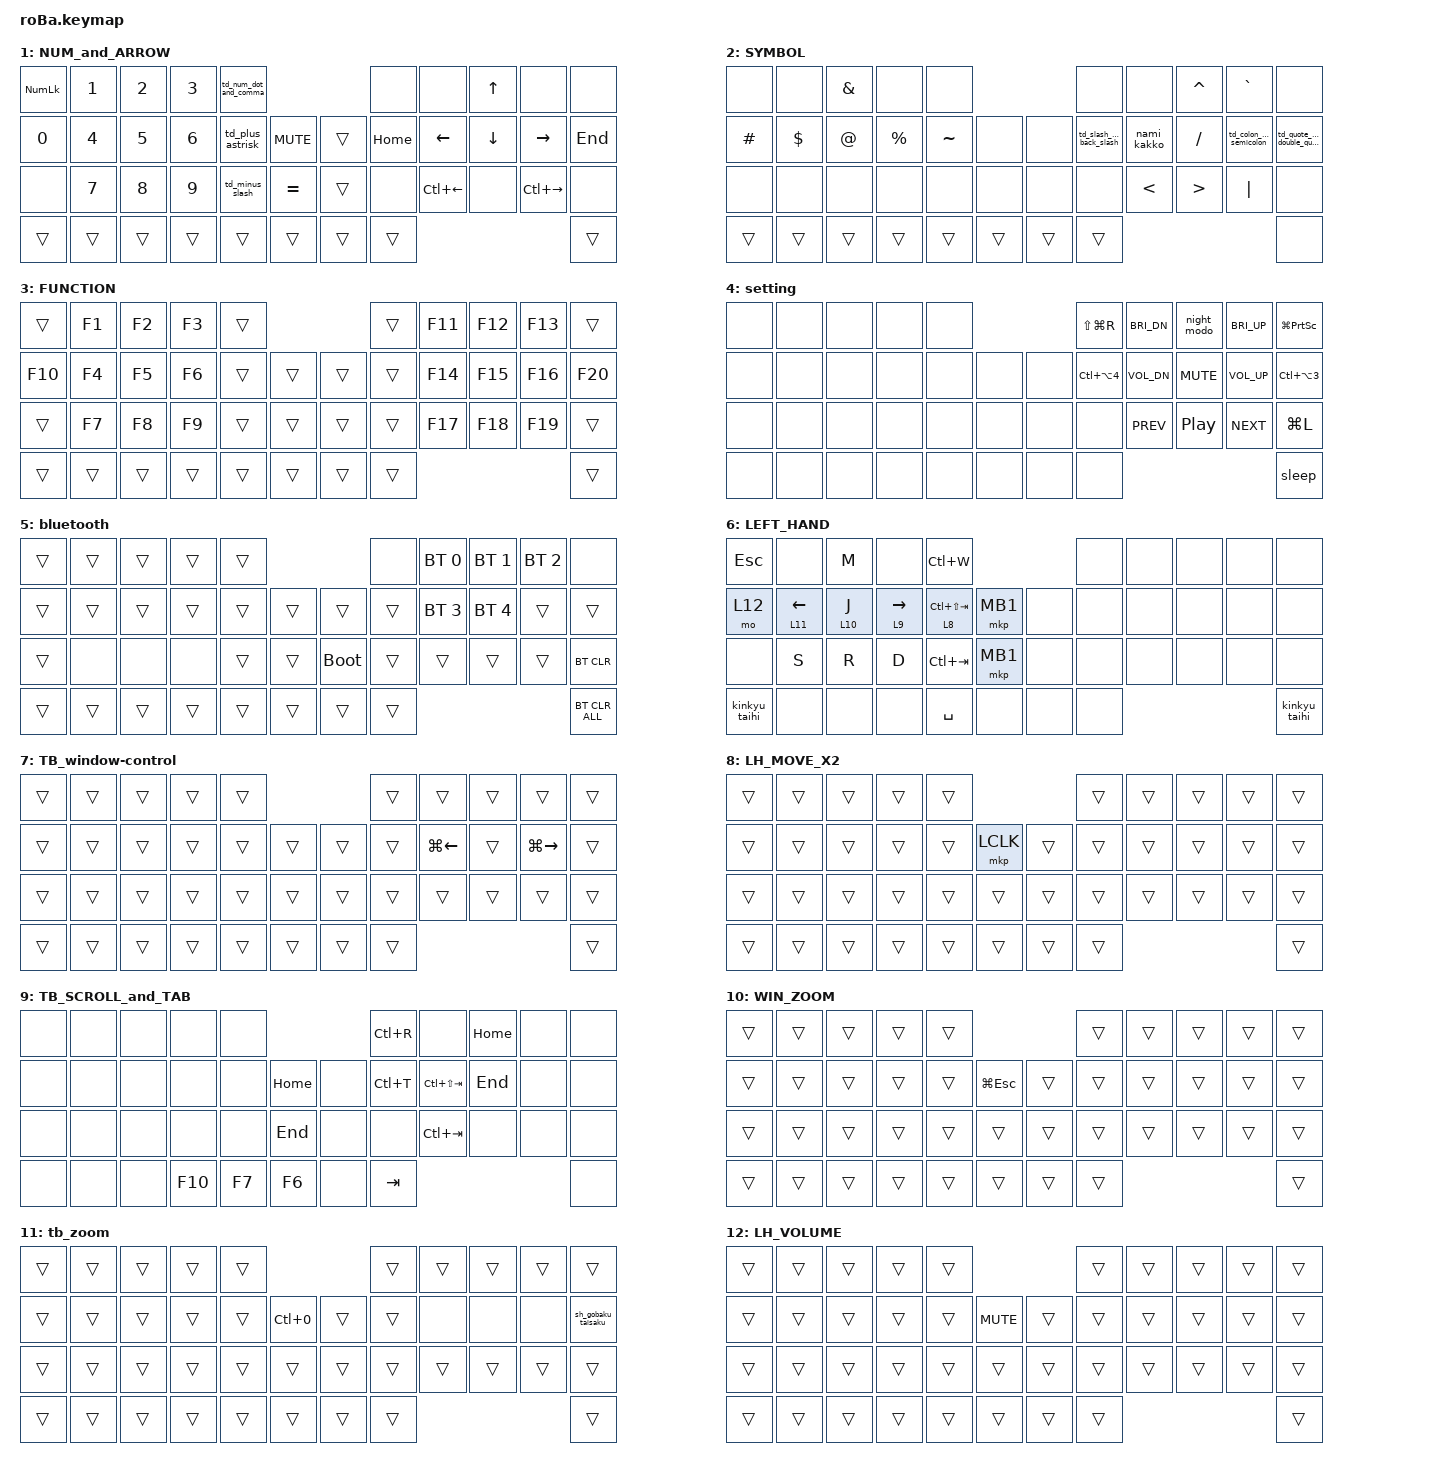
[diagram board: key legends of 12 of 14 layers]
#include <behaviors.dtsi>
#include <dt-bindings/zmk/bt.h>
#include <dt-bindings/zmk/keys.h>
#include <dt-bindings/zmk/pointing.h>

#define ZMK_POINTING_DEFAULT_SCRL_VAL 65

&mt {
    flavor = "balanced";
    quick-tap-ms = <0>;
};

// 長押しキー(&lt)の誤爆対策：
// 直前0.15秒以内に他のキーを押していたら（＝文字を打ってる途中なら）、長押しにせず普通の文字として扱う

&lt { require-prior-idle-ms = <150>; };

// エンコーダー: 1周12カチッ → 1カチッ=1入力

&left_encoder { steps = <48>; };

&sensors { triggers-per-rotation = <12>; };

// エンコーダーのカーソル移動用：マウス移動を最初から最高速にする
// （初期設定は0.3秒かけて加速するので、1カチッ(0.03秒)だとほぼ動かない）

&mmv { time-to-max-speed-ms = <0>; };

&trackball {
    scroll-layers = <9>;

    // レイヤー13(SNIPE)の間はボールがゆっくり（速さは roBa_R.conf の SNIPE_CPI）

    snipe-layers = <13>;

    // レイヤー7(TB_window-control)中にボールを転がすとウィンドウ操作
    // 4方向ともCtrl+Alt+Win+矢印を送り、AutoHotkey(roba-window.ahk)が受け取って動かす
    // (左右はWindowsのスナップに変換、連続入力はAutoHotkey側で無視)
    // 並び順: 右, 左, 上, 下

    gesture {
        layers = <7>;
        bindings =
            <&kp LC(LA(LG(RIGHT_ARROW)))>,
            <&kp LC(LA(LG(LEFT_ARROW)))>,
            <&kp LC(LA(LG(UP_ARROW)))>,
            <&kp LC(LA(LG(DOWN_ARROW)))>;

        tick = <300>;
        wait-ms = <300>;
        tap-ms = <5>;
    };

    // レイヤー11(tb_zoom)中にボールを上下で拡大・縮小
    // 左右には何も割り当てない(横のブレは捨てる)

    zoom {
        layers = <11>;
        bindings = <&none>, <&none>, <&kp LC(EQUAL)>, <&kp LC(MINUS)>;

        tick = <200>;
        wait-ms = <5>;
        tap-ms = <5>;
    };
};

/ {
    combos {
        compatible = "zmk,combos";

        // 精密モード：S＋H を同時に押してる間だけボールがゆっくり
        // （文字を打ってる途中＝直前0.15秒以内にキーを押してた時は発動しない）

        snipe_sh {
            bindings = <&mo 13>;
            key-positions = <20 21>;
            layers = <0>;
            timeout-ms = <40>;
            require-prior-idle-ms = <150>;
        };

        left-click {
            bindings = <&mkp LCLK>;
            key-positions = <18 19>;
        };

        middle-click {
            bindings = <&mkp MCLK>;
            key-positions = <18 19 20>;
        };

        right-click {
            bindings = <&mkp RCLK>;
            key-positions = <19 20>;
        };

        prev-click {
            bindings = <&mkp MB4>;
            key-positions = <30 31>;
        };

        next-click {
            bindings = <&mkp MB5>;
            key-positions = <31 32>;
        };

        new-tab {
            bindings = <&kp LC(T)>;
            key-positions = <16 28>;
        };

        LANG_1 {
            bindings = <&kp LANG1>;
            key-positions = <14 17>;
            layers = <0>;
        };

        LANG_2 {
            bindings = <&kp LANG2>;
            key-positions = <29 26>;
            layers = <0>;
        };

        Mission_Control {
            bindings = <&kp LG(TAB)>;
            key-positions = <18 20>;
        };

        Show_Desktop {
            bindings = <&kp LG(D)>;
            key-positions = <20 30>;
        };

        LEFT_HAND {
            bindings = <&to 6>;
            key-positions = <0 1>;
        };

        LEFT_HAND_TO_LAYER_0 {
            bindings = <&to 0>;
            key-positions = <19 12>;
            layers = <6>;
        };

        LEFT_HAND_TO_LAYER_0_SUB {
            bindings = <&to 0>;
            key-positions = <8 9>;
            layers = <6>;
        };

        henkan_Secret {
            bindings = <&henkan_Secret>;
            key-positions = <2 1>;
        };

        bluetooth-setting {
            bindings = <&mo 5>;
            key-positions = <0 1 2>;
        };

        reset-button {
            bindings = <&sys_reset>;
            key-positions = <3 4 5 6>;
        };
    };

    macros {
        to_layer_0: to_layer_0 {
            compatible = "zmk,behavior-macro-one-param";
            #binding-cells = <1>;
            bindings = <&to 0 &macro_param_1to1 &kp MACRO_PLACEHOLDER>;
            label = "TO_LAYER_0";
        };

        kakko: kakko {
            compatible = "zmk,behavior-macro";
            #binding-cells = <0>;
            bindings = <&kp LEFT_PARENTHESIS &kp RIGHT_PARENTHESIS &kp LEFT_ARROW>;
            label = "KAKKO";
        };

        sleep: sleep {
            compatible = "zmk,behavior-macro";
            #binding-cells = <0>;
            bindings =
                <&macro_wait_time 300>,
                <&kp LANG2 &kp LG(X) &kp U &kp S>;

            label = "SLEEP";
        };

        sh_gobaku_taisaku: sh_gobaku_taisaku {
            compatible = "zmk,behavior-macro";
            #binding-cells = <0>;
            bindings = <&kp S &kp H>;
            label = "SH_GOBAKU_TAISAKU";
        };

        night_modo: night_modo {
            compatible = "zmk,behavior-macro";
            #binding-cells = <0>;
            bindings = <&macro_wait_time 400>, <&kp LG(A) &kp SPACE &kp ESCAPE>;

            label = "NIGHT_MODO";
        };

        kagikakko: kagikakko {
            compatible = "zmk,behavior-macro";
            #binding-cells = <0>;
            bindings = <&kp LBKT &kp RBKT &kp LEFT_ARROW>;
            label = "KAGIKAKKO";
        };

        nami_kakko: nimi_kakko {
            compatible = "zmk,behavior-macro";
            #binding-cells = <0>;
            bindings = <&kp LBRC &kp RBRC &kp LEFT_ARROW>;
            label = "NIMI_KAKKO";
        };

        kinkyu_taihi: kinkyu_taihi {
            compatible = "zmk,behavior-macro";
            #binding-cells = <0>;
            bindings = <&kp C_MUTE &kp LG(D)>;
            label = "KINKYU_TAIHI";
        };

        henkan_Secret: henkan_Secret {
            compatible = "zmk,behavior-macro";
            #binding-cells = <0>;
            bindings = <&kp LANG1 &kp K &kp O &kp M &kp A &kp N &kp D &kp O &kp SPACE>;
            label = "HENKAN_SECRET";
        };
    };

    behaviors {
        // ZXCVのタップダンス用の「長押しで修飾キー」：
        // 文字を打ってる途中（直前0.15秒以内にキーを押してた時）は、待たずにすぐ「文字」に決める
        // → 「ざ」を速く打った時に「あz」と順番が入れ替わるのを防ぐ

        mt_td: mt_for_tapdance {
            compatible = "zmk,behavior-hold-tap";
            label = "MT_FOR_TAPDANCE";
            #binding-cells = <2>;
            flavor = "balanced";
            tapping-term-ms = <200>;
            quick-tap-ms = <0>;
            require-prior-idle-ms = <150>;
            bindings = <&kp>, <&kp>;
        };

        // S・H用の長押し：次に「左手」のキーを押した時（またはそのまま長押しした時）だけレイヤーにする
        // 右手で続けて打った時（sh、su など）は普通の文字になる

        lt_oh: lt_other_hand {
            compatible = "zmk,behavior-hold-tap";
            label = "LT_OTHER_HAND";
            #binding-cells = <2>;
            flavor = "tap-preferred";
            tapping-term-ms = <200>;
            require-prior-idle-ms = <150>;
            hold-trigger-key-positions = <0 1 2 3 4 10 11 12 13 14 15 22 23 24 25 26 27 34 35 36 37 38 39>;
            bindings = <&mo>, <&kp>;
        };

        // 単体押し:BS / 長押し:レイヤー2(SYMBOL) / 1回押してすぐ長押し:BS連打

        lt_bs: lt_bs {
            compatible = "zmk,behavior-hold-tap";
            #binding-cells = <2>;
            flavor = "tap-preferred";
            tapping-term-ms = <200>;
            quick-tap-ms = <200>;
            bindings = <&mo>, <&kp>;
        };

        lt_to_layer_0: lt_to_layer_0 {
            compatible = "zmk,behavior-hold-tap";
            label = "LAYER_TAP_TO_0";
            bindings = <&mo>, <&to_layer_0>;

            #binding-cells = <2>;
            tapping-term-ms = <200>;
        };

        // エンコーダーでマウスカーソルを左右に動かす（1カチッごとに tap-ms の間だけ動く）
        // エンコーダーでカーソルを倍の量で左右に動かす（tap-ms を通常版の2倍に）

        encoder_mmv_left_right_x2: encoder_mmv_left_right_x2 {
            compatible = "zmk,behavior-sensor-rotate";
            label = "ENCODER_MMV_LEFT_RIGHT_X2";
            #sensor-binding-cells = <0>;
            bindings = <&mmv MOVE_RIGHT>, <&mmv MOVE_LEFT>;

            tap-ms = <60>;
        };

        encoder_mmv_left_right: encoder_mmv_left_right {
            compatible = "zmk,behavior-sensor-rotate";
            label = "ENCODER_MMV_LEFT_RIGHT";
            #sensor-binding-cells = <0>;
            bindings = <&mmv MOVE_RIGHT>, <&mmv MOVE_LEFT>;

            tap-ms = <30>;
        };

        encoder_msc_down_up: encoder_msc_down_up {
            compatible = "zmk,behavior-sensor-rotate";
            label = "ENCODER_MSC_DOWN_UP";
            #sensor-binding-cells = <0>;
            bindings = <&msc SCRL_DOWN>, <&msc SCRL_UP>;

            // 追加: スクロールのタップ時間を設定 (20ms)

            tap-ms = <20>;
        };

        td_c: td_c {
            compatible = "zmk,behavior-tap-dance";
            label = "TD_C";
            #binding-cells = <0>;
            bindings = <&mt_td LEFT_SHIFT C>, <&kp LC(C)>;
        };

        td_v: td_v {
            compatible = "zmk,behavior-tap-dance";
            label = "TD_V";
            #binding-cells = <0>;
            bindings = <&mt_td LEFT_WIN V>, <&kp LC(V)>, <&kp LG(V)>;
        };

        td_x: td_x {
            compatible = "zmk,behavior-tap-dance";
            label = "TD_X";
            #binding-cells = <0>;
            bindings = <&mt_td LEFT_ALT X>, <&kp LC(X)>;
        };

        // Q：1回=q（長押しでbluetoothレイヤー）／2回=元に戻す(Ctrl+Z)

        td_q: td_q {
            compatible = "zmk,behavior-tap-dance";
            label = "TD_Q";
            #binding-cells = <0>;
            tapping-term-ms = <300>;  // 2回押しの受付時間（初期値200）。Qはほぼ打たないので長めでOK
            bindings = <&kp Q>, <&kp LC(Z)>;
        };

        // L：1回=l／2回=やり直し(Ctrl+Y)
        // 文字を打ってる途中で次のキーを押せば、待たずにすぐ l に決まる

        td_l: td_l {
            compatible = "zmk,behavior-tap-dance";
            label = "TD_L";
            #binding-cells = <0>;
            bindings = <&kp L>, <&kp LC(Y)>;
        };

        td_question: td_question {
            compatible = "zmk,behavior-tap-dance";
            label = "TD_QUESTION";
            #binding-cells = <0>;
            bindings = <&kp QUESTION>, <&kp LS(NUMBER_1)>;
        };

        td_plus_astrisk: td_plus_astrisk {
            compatible = "zmk,behavior-tap-dance";
            label = "TD_PLUS_ASTRISK";
            #binding-cells = <0>;
            bindings = <&kp PLUS>, <&kp ASTRK>;
        };

        td_minus_slash: td_minus_slash {
            compatible = "zmk,behavior-tap-dance";
            label = "TD_MINUS_SLASH";
            #binding-cells = <0>;
            bindings = <&kp KP_MINUS>, <&kp KP_SLASH>;
        };

        td_comma_dot: td_comma_dot {
            compatible = "zmk,behavior-tap-dance";
            label = "TD_COMMA_DOT";
            #binding-cells = <0>;
            bindings = <&kp COMMA>, <&kp DOT>;
        };

        td_kakko_kagikakko: td_kakko_kagikakko {
            compatible = "zmk,behavior-tap-dance";
            label = "TD_KAKKO_KAGIKAKKO";
            #binding-cells = <0>;
            bindings = <&kakko>, <&kagikakko>;
        };

        td_slash_and_back_slash: td_slash_and_back_slash {
            compatible = "zmk,behavior-tap-dance";
            label = "TD_SLASH_AND_BACK_SLASH";
            #binding-cells = <0>;
            bindings = <&kp KP_DIVIDE>, <&kp BACKSLASH>;
        };

        td_colon_and_semicolon: td_colon_and_semicolon {
            compatible = "zmk,behavior-tap-dance";
            label = "TD_COLON_AND_SEMICOLON";
            #binding-cells = <0>;
            bindings = <&kp COLON>, <&kp SEMICOLON>;
        };

        td_quote_and_double_quote: td_quote_and_double_quote {
            compatible = "zmk,behavior-tap-dance";
            label = "TD_QUOTE_AND_DOUBLE_QUOTE";
            #binding-cells = <0>;
            bindings = <&kp SINGLE_QUOTE>, <&kp DQT>;
        };

        td_num_dot_and_comma: td_num_dot_and_comma {
            compatible = "zmk,behavior-tap-dance";
            label = "TD_NUM_DOT_AND_COMMA";
            #binding-cells = <0>;
            bindings = <&kp COMMA>, <&kp KP_DOT>;
        };
    };

    keymap {
        compatible = "zmk,keymap";

        default_layer {
            bindings = <
&td_q           &td_l   &kp U   &td_comma_dot      &td_kakko_kagikakko                                              &kp F        &kp W            &kp R              &kp Y            &kp P
&kp E           &kp I   &kp A   &kp O              &kp MINUS            &kp C_MUTE                 &kp LC(LS(TAB))  &kp K        &kp T            &lt 7 N            &lt_oh 11 S      &lt_oh 9 H
&mt_td LCTRL Z  &td_x   &td_c   &td_v              &td_question         &kp LC(LA(LG(K)))          &kp LC(TAB)      &kp G        &mt RIGHT_WIN D  &mt RIGHT_SHIFT M  &mt RIGHT_ALT J  &mt RCTRL B
&kinkyu_taihi   &trans  &trans  &kp LC(BACKSPACE)  &lt_bs 2 BACKSPACE   &mt LEFT_SHIFT DELETE      &lt 4 ENTER      &lt 1 SPACE                                                       &kp ESCAPE
            >;

            sensor-bindings = <&inc_dec_kp C_VOL_DN C_VOL_UP>;
        };

        NUM_and_ARROW {
            bindings = <
&kp KP_NUMLOCK  &kp N1        &kp N2        &kp N3        &td_num_dot_and_comma                          &none     &none               &kp UP_ARROW    &none                &none
&kp NUMBER_0    &kp N4        &kp NUMBER_5  &kp N6        &td_plus_astrisk       &kp C_MUTE      &trans  &kp HOME  &kp LEFT_ARROW      &kp DOWN_ARROW  &kp RIGHT_ARROW      &kp END
&none           &kp NUMBER_7  &kp NUMBER_8  &kp NUMBER_9  &td_minus_slash        &kp EQUAL       &trans  &none     &kp LC(LEFT_ARROW)  &none           &kp LC(RIGHT_ARROW)  &none
&trans          &trans        &trans        &trans        &trans                 &trans          &trans  &trans                                                             &trans
            >;

            sensor-bindings = <&inc_dec_kp LC(C_VOL_DN) LC(C_VOL_UP)>;
        };

        SYMBOL {
            bindings = <
&none     &none       &kp AMPERSAND  &none        &none                          &none                     &none          &kp CARET         &kp GRAVE                &none
&kp HASH  &kp DOLLAR  &kp AT         &kp PERCENT  &kp TILDE  &none       &none   &td_slash_and_back_slash  &nami_kakko    &kp SLASH         &td_colon_and_semicolon  &td_quote_and_double_quote
&none     &none       &none          &none        &none      &none       &none   &none                     &kp LESS_THAN  &kp GREATER_THAN  &kp PIPE                 &none
&trans    &trans      &trans         &trans       &trans     &trans      &trans  &trans                                                                              &none
            >;
        };

        FUNCTION {
            bindings = <
&trans   &kp F1  &kp F2  &kp F3  &trans                      &trans  &kp F11  &kp F12  &kp F13  &trans
&kp F10  &kp F4  &kp F5  &kp F6  &trans  &trans      &trans  &trans  &kp F14  &kp F15  &kp F16  &kp F20
&trans   &kp F7  &kp F8  &kp F9  &trans  &trans      &trans  &trans  &kp F17  &kp F18  &kp F19  &trans
&trans   &trans  &trans  &trans  &trans  &trans      &trans  &trans                             &trans
            >;
        };

        setting {
            bindings = <
&none  &none  &none  &none  &none                    &kp LS(LG(R))   &kp C_BRI_DN  &night_modo       &kp C_BRI_UP  &kp LG(PRINTSCREEN)
&none  &none  &none  &none  &none  &none      &none  &kp LC(LA(N4))  &kp C_VOL_DN  &kp C_MUTE        &kp C_VOL_UP  &kp LC(LA(N3))
&none  &none  &none  &none  &none  &none      &none  &none           &kp C_PREV    &kp C_PLAY_PAUSE  &kp C_NEXT    &kp LG(L)
&none  &none  &none  &none  &none  &none      &none  &none                                                         &sleep
            >;
        };

        bluetooth {
            bindings = <
&trans  &trans  &trans  &trans  &trans                           &none   &bt BT_SEL 0  &bt BT_SEL 1  &bt BT_SEL 2  &none
&trans  &trans  &trans  &trans  &trans  &trans      &trans       &trans  &bt BT_SEL 3  &bt BT_SEL 4  &trans        &trans
&trans  &none   &none   &none   &trans  &trans      &bootloader  &trans  &trans        &trans        &trans        &bt BT_CLR
&trans  &trans  &trans  &trans  &trans  &trans      &trans       &trans                                            &bt BT_CLR_ALL
            >;
        };

        LEFT_HAND {
            bindings = <
&kp ESC        &none              &kp M     &none              &kp LC(W)                               &none  &none  &none  &none  &none
&mo 12         &lt 11 LEFT_ARROW  &lt 10 J  &lt 9 RIGHT_ARROW  &lt 8 LC(LS(TAB))  &mkp MB1      &none  &none  &none  &none  &none  &none
&none          &kp S              &kp R     &kp D              &kp LC(TAB)        &mkp MB1      &none  &none  &none  &none  &none  &none
&kinkyu_taihi  &none              &none     &none              &kp SPACE          &none         &none  &none                       &kinkyu_taihi
            >;

            // 何も押してない時：カーソルを左右に移動（長押し中は上のレイヤーが優先される）

            sensor-bindings = <&encoder_mmv_left_right>;
        };

        TB_window-control {
            bindings = <
&trans  &trans  &trans  &trans  &trans                      &trans  &trans              &trans  &trans               &trans
&trans  &trans  &trans  &trans  &trans  &trans      &trans  &trans  &kp LG(LEFT_ARROW)  &trans  &kp LG(RIGHT_ARROW)  &trans
&trans  &trans  &trans  &trans  &trans  &trans      &trans  &trans  &trans              &trans  &trans               &trans
&trans  &trans  &trans  &trans  &trans  &trans      &trans  &trans                                                   &trans
            >;
        };

        // 左手モード中の長押し（-）：カーソルを倍の量で左右移動／押し込み＝左クリック

        LH_MOVE_X2 {
            bindings = <
&trans  &trans  &trans  &trans  &trans                         &trans  &trans  &trans  &trans  &trans
&trans  &trans  &trans  &trans  &trans  &mkp LCLK      &trans  &trans  &trans  &trans  &trans  &trans
&trans  &trans  &trans  &trans  &trans  &trans         &trans  &trans  &trans  &trans  &trans  &trans
&trans  &trans  &trans  &trans  &trans  &trans         &trans  &trans                          &trans
            >;

            sensor-bindings = <&encoder_mmv_left_right_x2>;
        };

        TB_SCROLL_and_TAB {
            bindings = <
&none  &none  &none  &none    &none                        &kp LC(R)  &none            &kp HOME  &none  &none
&none  &none  &none  &none    &none   &kp HOME      &none  &kp LC(T)  &kp LC(LS(TAB))  &kp END   &none  &none
&none  &none  &none  &none    &none   &kp END       &none  &none      &kp LC(TAB)      &none     &none  &none
&none  &none  &none  &kp F10  &kp F7  &kp F6        &none  &kp TAB                                      &none
            >;

            sensor-bindings = <&encoder_msc_down_up>;
        };

        WIN_ZOOM {
            bindings = <
&trans  &trans  &trans  &trans  &trans                           &trans  &trans  &trans  &trans  &trans
&trans  &trans  &trans  &trans  &trans  &kp LG(ESC)      &trans  &trans  &trans  &trans  &trans  &trans
&trans  &trans  &trans  &trans  &trans  &trans           &trans  &trans  &trans  &trans  &trans  &trans
&trans  &trans  &trans  &trans  &trans  &trans           &trans  &trans                          &trans
            >;

            sensor-bindings = <&inc_dec_kp LG(MINUS) LG(EQUAL)>;
        };

        tb_zoom {
            bindings = <
&trans  &trans  &trans  &trans  &trans                                &trans  &trans  &trans  &trans  &trans
&trans  &trans  &trans  &trans  &trans  &kp LC(NUMBER_0)      &trans  &trans  &none   &none   &none   &sh_gobaku_taisaku
&trans  &trans  &trans  &trans  &trans  &trans                &trans  &trans  &trans  &trans  &trans  &trans
&trans  &trans  &trans  &trans  &trans  &trans                &trans  &trans                          &trans
            >;

            sensor-bindings = <&inc_dec_kp LC(MINUS) LC(PLUS)>;
        };

        // 左手モード中の長押し（E）：音量／押し込み＝ミュート

        LH_VOLUME {
            bindings = <
&trans  &trans  &trans  &trans  &trans                          &trans  &trans  &trans  &trans  &trans
&trans  &trans  &trans  &trans  &trans  &kp C_MUTE      &trans  &trans  &trans  &trans  &trans  &trans
&trans  &trans  &trans  &trans  &trans  &trans          &trans  &trans  &trans  &trans  &trans  &trans
&trans  &trans  &trans  &trans  &trans  &trans          &trans  &trans                          &trans
            >;

            sensor-bindings = <&inc_dec_kp C_VOL_DN C_VOL_UP>;
        };

        // 精密モード：S＋Hを同時に押してる間だけボールがゆっくり。T＝左クリック、N＝右クリック（T＋N同時押しの左クリックもそのまま使える）

        SNIPE {
            bindings = <
&trans  &trans  &trans  &trans  &trans                      &trans  &trans     &trans     &trans  &trans
&trans  &trans  &trans  &trans  &trans  &trans      &trans  &trans  &mkp LCLK  &mkp RCLK  &trans  &trans
&trans  &trans  &trans  &trans  &trans  &trans      &trans  &trans  &trans     &trans     &trans  &trans
&trans  &trans  &trans  &trans  &trans  &trans      &trans  &trans                                &trans
            >;
        };
    };
};
